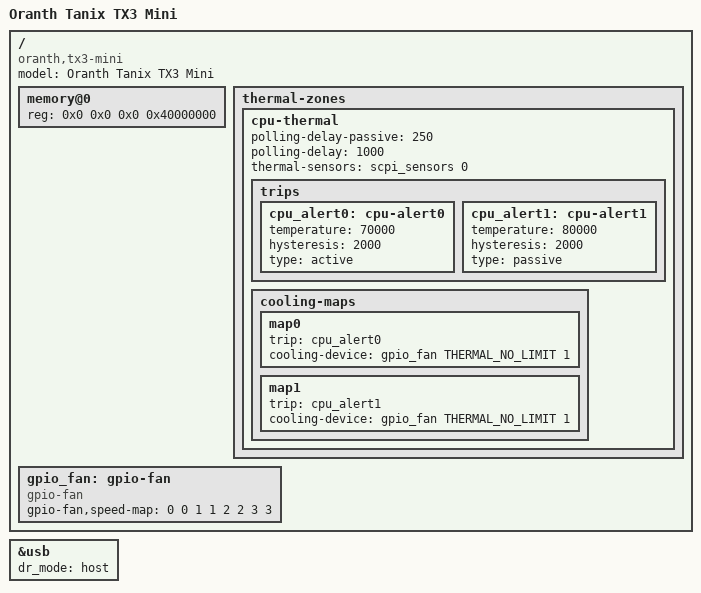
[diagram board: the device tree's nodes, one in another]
// SPDX-License-Identifier: (GPL-2.0+ OR MIT)
/*
 * Copyright (c) 2018 Martin Blumenstingl <martin.blumenstingl@googlemail.com>.
 * Based on meson-gxl-s905d-p231.dts:
 * - Copyright (c) 2016 Endless Computers, Inc.
 *   Author: Carlo Caione <carlo@endlessm.com>
 */

/dts-v1/;

#include "meson-gxl-s905x.dtsi"
#include "meson-gx-p23x-q20x.dtsi"
#include <dt-bindings/thermal/thermal.h>

/ {
	compatible = "oranth,tx3-mini", "amlogic,s905w", "amlogic,meson-gxl";
	model = "Oranth Tanix TX3 Mini";

	memory@0 {
		device_type = "memory";
		reg = <0x0 0x0 0x0 0x40000000>; /* 1 GiB or 2 GiB */
	};

	thermal-zones {
		cpu-thermal {
			polling-delay-passive = <250>; /* milliseconds */
			polling-delay = <1000>; /* milliseconds */

			thermal-sensors = <&scpi_sensors 0>;

			trips {
				cpu_alert0: cpu-alert0 {
					temperature = <70000>; /* millicelsius */
					hysteresis = <2000>; /* millicelsius */
					type = "active";
				};

				cpu_alert1: cpu-alert1 {
					temperature = <80000>; /* millicelsius */
					hysteresis = <2000>; /* millicelsius */
					type = "passive";
				};
			};

			cooling-maps {
				map0 {
					trip = <&cpu_alert0>;
					cooling-device = <&gpio_fan THERMAL_NO_LIMIT 1>;
				};

				map1 {
					trip = <&cpu_alert1>;
					cooling-device = <&gpio_fan THERMAL_NO_LIMIT 1>;
				};
			};
		};
	};

	gpio_fan: gpio-fan {
		compatible = "gpio-fan";
		/* Dummy RPM values since fan is optional */
		gpio-fan,speed-map = <0 0
				      1 1
				      2 2
				      3 3>;
		#cooling-cells = <2>;
	};
};

&usb {
	dr_mode = "host";
};
